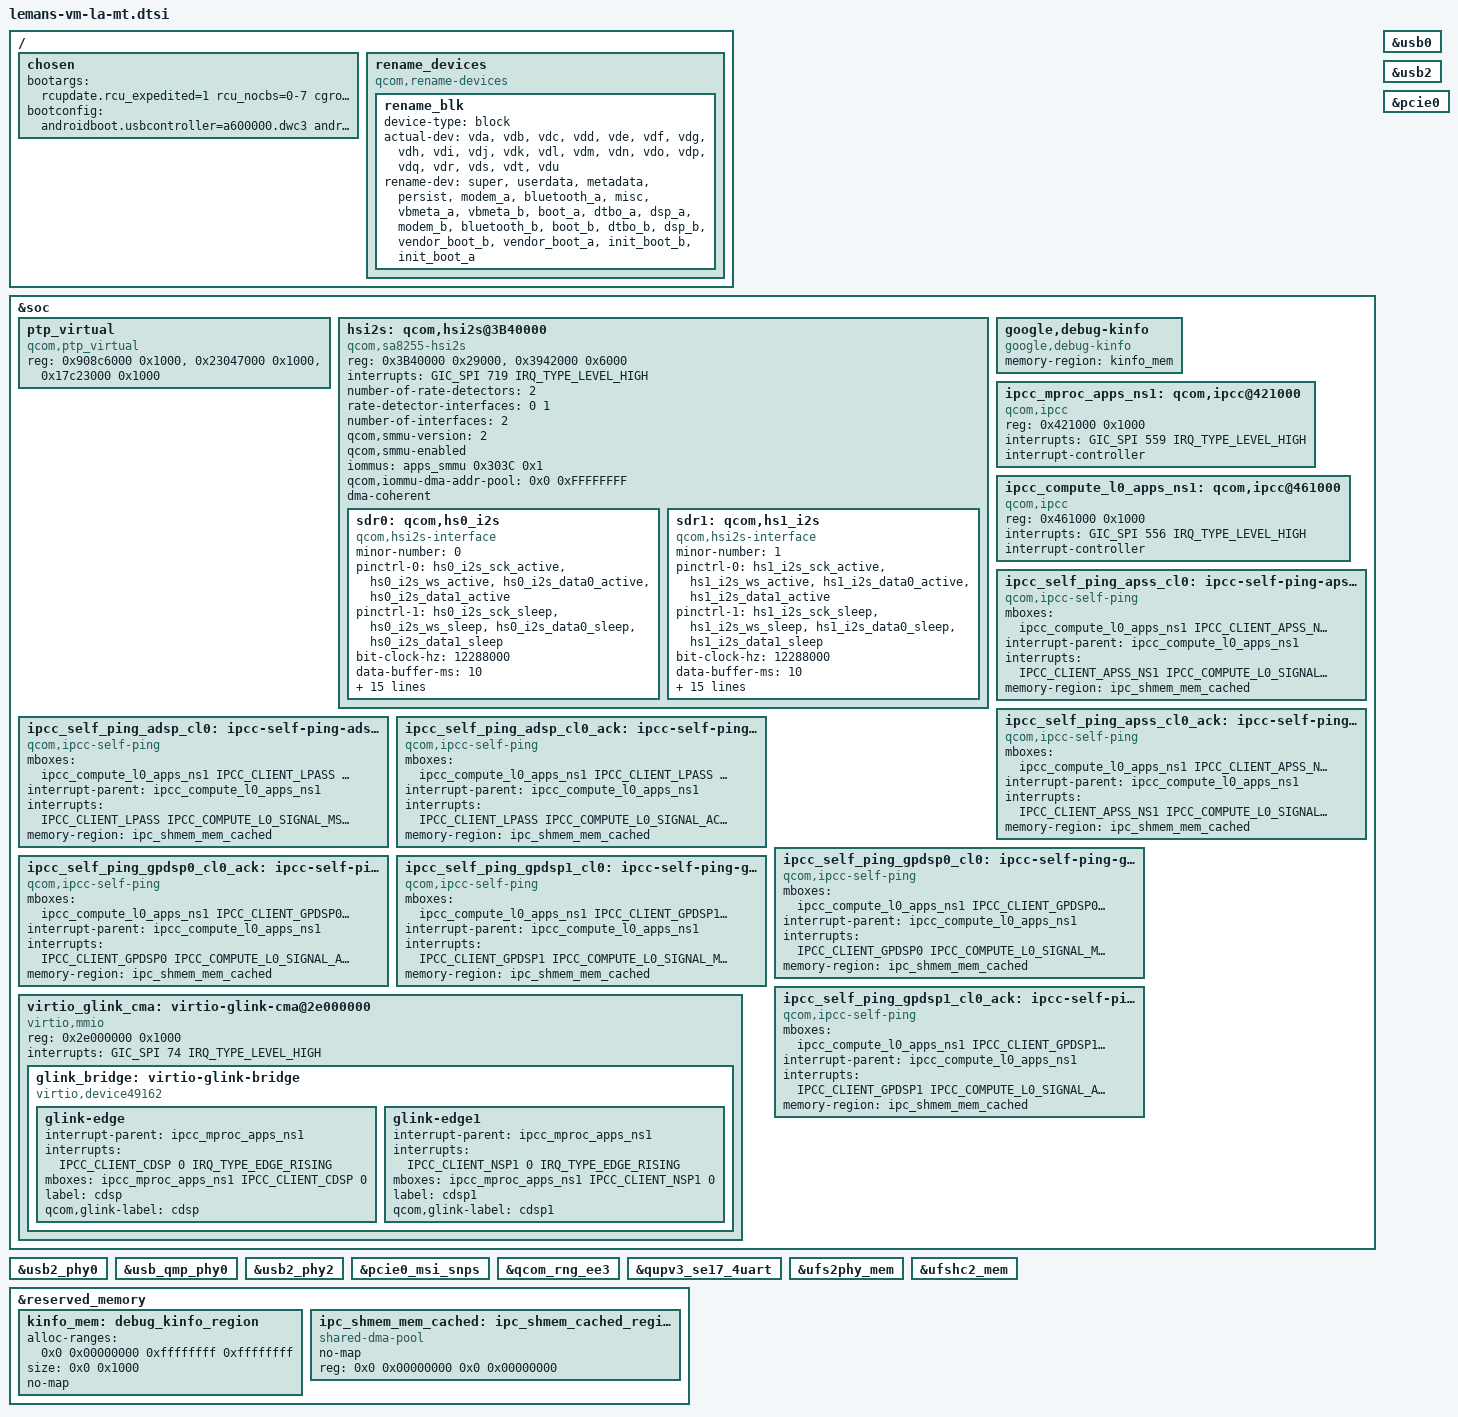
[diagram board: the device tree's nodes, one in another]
#include <dt-bindings/mailbox/qcom-ipcc.h>

&soc {
	ptp_virtual {
		compatible = "qcom,ptp_virtual";
		reg = <0x908c6000 0x1000>,
			<0x23047000 0x1000>,
			<0x17c23000 0x1000>;
		reg-names = "ptp_carveout_mem",
				"ptp_reg",
				"qtimer_reg";
	};

	hsi2s: qcom,hsi2s@3B40000 {
		compatible = "qcom,sa8255-hsi2s", "qcom,hsi2s";
		reg = <0x3B40000 0x29000>,
			<0x3942000 0x6000>;
		reg-names = "lpa_if", "lpass_core_cc_hs_if";
		interrupts = <GIC_SPI 719 IRQ_TYPE_LEVEL_HIGH>;
		number-of-rate-detectors = <2>;
		rate-detector-interfaces = <0 1>;
		number-of-interfaces = <2>;
		qcom,smmu-version = <2>;
		qcom,smmu-enabled;
		iommus = <&apps_smmu 0x303C 0x1>;
		qcom,iommu-dma-addr-pool = <0x0 0xFFFFFFFF>;
		dma-coherent;

		sdr0: qcom,hs0_i2s {
			compatible = "qcom,hsi2s-interface";
			minor-number = <0>;
			pinctrl-names = "default", "sleep";
			pinctrl-0 = <&hs0_i2s_sck_active
				     &hs0_i2s_ws_active &hs0_i2s_data0_active
				     &hs0_i2s_data1_active>;
			pinctrl-1 = <&hs0_i2s_sck_sleep
				     &hs0_i2s_ws_sleep &hs0_i2s_data0_sleep
				     &hs0_i2s_data1_sleep>;
			bit-clock-hz = <12288000>;
			data-buffer-ms = <10>;
			bit-depth = <32>;
			spkr-channel-count = <2>;
			mic-channel-count = <2>;
			pcm-rate = <2>;
			pcm-sync-src = <0>;
			aux-mode = <0>;
			rpcm-width = <1>;
			tpcm-width = <1>;
			enable-tdm = <1>;
			tdm-rate = <32>;
			tdm-rpcm-width = <16>;
			tdm-tpcm-width = <16>;
			tdm-sync-delay = <2>;
			tdm-inv-sync = <0>;
			pcm-lane-config = <1>;
		};

		sdr1: qcom,hs1_i2s {
			compatible = "qcom,hsi2s-interface";
			minor-number = <1>;
			pinctrl-names = "default", "sleep";
			pinctrl-0 = <&hs1_i2s_sck_active
				     &hs1_i2s_ws_active &hs1_i2s_data0_active
				     &hs1_i2s_data1_active>;
			pinctrl-1 = <&hs1_i2s_sck_sleep
				     &hs1_i2s_ws_sleep &hs1_i2s_data0_sleep
				     &hs1_i2s_data1_sleep>;
			bit-clock-hz = <12288000>;
			data-buffer-ms = <10>;
			bit-depth = <32>;
			spkr-channel-count = <2>;
			mic-channel-count = <2>;
			pcm-rate = <2>;
			pcm-sync-src = <0>;
			aux-mode = <0>;
			rpcm-width = <1>;
			tpcm-width = <1>;
			enable-tdm = <1>;
			tdm-rate = <32>;
			tdm-rpcm-width = <16>;
			tdm-tpcm-width = <16>;
			tdm-sync-delay = <2>;
			tdm-inv-sync = <0>;
			pcm-lane-config = <1>;
		};
	};
};

/ {
	chosen {
		bootargs = "rcupdate.rcu_expedited=1 rcu_nocbs=0-7 cgroup.memory=nokmem,nosocket kpti=0 ufshcd-core.use_mcq_mode=n arm64.nopauth kasan=off msm_show_resume_irq.debug_mask=1";
		bootconfig = "androidboot.usbcontroller=a600000.dwc3 androidboot.fstab_suffix=gen4.qcom androidboot.dtbo_idx=2";
	};

	rename_devices: rename_devices {
		compatible = "qcom,rename-devices";
		rename_blk: rename_blk {
			device-type = "block";
			actual-dev = "vda", "vdb", "vdc",
					"vdd", "vde", "vdf",
					"vdg", "vdh", "vdi",
					"vdj", "vdk", "vdl",
					"vdm", "vdn", "vdo",
					"vdp", "vdq", "vdr",
					"vds", "vdt", "vdu";
			rename-dev = "super", "userdata", "metadata",
					"persist", "modem_a","bluetooth_a",
					"misc", "vbmeta_a", "vbmeta_b",
					"boot_a", "dtbo_a", "dsp_a",
					"modem_b", "bluetooth_b", "boot_b",
					"dtbo_b", "dsp_b", "vendor_boot_b",
					"vendor_boot_a", "init_boot_b", "init_boot_a";
		};
	};
};

&usb0 {
	status = "ok";
};

&usb2_phy0 {
	status = "ok";
};

&usb_qmp_phy0 {
	status = "ok";
};

&usb2 {
	status = "ok";
};

&usb2_phy2 {
	status = "ok";
};

&pcie0 {
	status = "ok";
};

&pcie0_msi_snps {
	status = "ok";
};

&qcom_rng_ee3 {
	status = "ok";
};

&qupv3_se17_4uart {
	status = "ok";
};

&ufs2phy_mem {
	status = "ok";
};

&ufshc2_mem {
	status = "ok";
};

&reserved_memory {
	kinfo_mem: debug_kinfo_region {
		alloc-ranges = <0x0 0x00000000 0xffffffff 0xffffffff>;
		size = <0x0 0x1000>;
		no-map;
	};

	ipc_shmem_mem_cached: ipc_shmem_cached_region {
		compatible = "shared-dma-pool";
		no-map;
		reg = <0x0 0x00000000 0x0 0x00000000>;
	};
};

&soc {
	google,debug-kinfo {
		compatible = "google,debug-kinfo";
		memory-region = <&kinfo_mem>;
	};

	ipcc_mproc_apps_ns1: qcom,ipcc@421000 {
		compatible = "qcom,ipcc";
		reg = <0x421000 0x1000>;
		interrupts = <GIC_SPI 559 IRQ_TYPE_LEVEL_HIGH>;
		interrupt-controller;
		#interrupt-cells = <3>;
		#mbox-cells = <2>;
	};

	ipcc_compute_l0_apps_ns1: qcom,ipcc@461000 {
		compatible = "qcom,ipcc";
		reg = <0x461000 0x1000>;
		interrupts = <GIC_SPI 556 IRQ_TYPE_LEVEL_HIGH>;
		interrupt-controller;
		#interrupt-cells = <3>;
		#mbox-cells = <2>;
		status = "ok";
	};

	ipcc_self_ping_apss_cl0: ipcc-self-ping-apss_cl0 {
		compatible = "qcom,ipcc-self-ping";
		mboxes = <&ipcc_compute_l0_apps_ns1 IPCC_CLIENT_APSS_NS1
				IPCC_COMPUTE_L0_SIGNAL_MSG>;
		interrupt-parent = <&ipcc_compute_l0_apps_ns1>;
		interrupts = <IPCC_CLIENT_APSS_NS1
				IPCC_COMPUTE_L0_SIGNAL_MSG
				IRQ_TYPE_EDGE_RISING>;
		memory-region = <&ipc_shmem_mem_cached>;
	};

	ipcc_self_ping_apss_cl0_ack: ipcc-self-ping-apss_cl0_ack {
		compatible = "qcom,ipcc-self-ping";
		mboxes = <&ipcc_compute_l0_apps_ns1 IPCC_CLIENT_APSS_NS1
				IPCC_COMPUTE_L0_SIGNAL_ACK>;
		interrupt-parent = <&ipcc_compute_l0_apps_ns1>;
		interrupts = <IPCC_CLIENT_APSS_NS1
				IPCC_COMPUTE_L0_SIGNAL_ACK
				IRQ_TYPE_EDGE_RISING>;
		memory-region = <&ipc_shmem_mem_cached>;
	};

	ipcc_self_ping_adsp_cl0: ipcc-self-ping-adsp_cl0 {
		compatible = "qcom,ipcc-self-ping";
		mboxes = <&ipcc_compute_l0_apps_ns1 IPCC_CLIENT_LPASS
				IPCC_COMPUTE_L0_SIGNAL_MSG>;
		interrupt-parent = <&ipcc_compute_l0_apps_ns1>;
		interrupts = <IPCC_CLIENT_LPASS
				IPCC_COMPUTE_L0_SIGNAL_MSG
				IRQ_TYPE_EDGE_RISING>;
		memory-region = <&ipc_shmem_mem_cached>;
	};

	ipcc_self_ping_adsp_cl0_ack: ipcc-self-ping-adsp_cl0_ack {
		compatible = "qcom,ipcc-self-ping";
		mboxes = <&ipcc_compute_l0_apps_ns1 IPCC_CLIENT_LPASS
				IPCC_COMPUTE_L0_SIGNAL_ACK>;
		interrupt-parent = <&ipcc_compute_l0_apps_ns1>;
		interrupts = <IPCC_CLIENT_LPASS
				IPCC_COMPUTE_L0_SIGNAL_ACK
				IRQ_TYPE_EDGE_RISING>;
		memory-region = <&ipc_shmem_mem_cached>;
	};

	ipcc_self_ping_gpdsp0_cl0: ipcc-self-ping-gpdsp0_cl0 {
		compatible = "qcom,ipcc-self-ping";
		mboxes = <&ipcc_compute_l0_apps_ns1 IPCC_CLIENT_GPDSP0
				IPCC_COMPUTE_L0_SIGNAL_MSG>;
		interrupt-parent = <&ipcc_compute_l0_apps_ns1>;
		interrupts = <IPCC_CLIENT_GPDSP0
				IPCC_COMPUTE_L0_SIGNAL_MSG
				IRQ_TYPE_EDGE_RISING>;
		memory-region = <&ipc_shmem_mem_cached>;
	};

	ipcc_self_ping_gpdsp0_cl0_ack: ipcc-self-ping-gpdsp0_cl0_ack {
		compatible = "qcom,ipcc-self-ping";
		mboxes = <&ipcc_compute_l0_apps_ns1 IPCC_CLIENT_GPDSP0
				IPCC_COMPUTE_L0_SIGNAL_ACK>;
		interrupt-parent = <&ipcc_compute_l0_apps_ns1>;
		interrupts = <IPCC_CLIENT_GPDSP0
				IPCC_COMPUTE_L0_SIGNAL_ACK
				IRQ_TYPE_EDGE_RISING>;
		memory-region = <&ipc_shmem_mem_cached>;
	};

	ipcc_self_ping_gpdsp1_cl0: ipcc-self-ping-gpdsp1_cl0 {
		compatible = "qcom,ipcc-self-ping";
		mboxes = <&ipcc_compute_l0_apps_ns1 IPCC_CLIENT_GPDSP1
				IPCC_COMPUTE_L0_SIGNAL_MSG>;
		interrupt-parent = <&ipcc_compute_l0_apps_ns1>;
		interrupts = <IPCC_CLIENT_GPDSP1
				IPCC_COMPUTE_L0_SIGNAL_MSG
				IRQ_TYPE_EDGE_RISING>;
		memory-region = <&ipc_shmem_mem_cached>;
	};

	ipcc_self_ping_gpdsp1_cl0_ack: ipcc-self-ping-gpdsp1_cl0_ack {
		compatible = "qcom,ipcc-self-ping";
		mboxes = <&ipcc_compute_l0_apps_ns1 IPCC_CLIENT_GPDSP1
				IPCC_COMPUTE_L0_SIGNAL_ACK>;
		interrupt-parent = <&ipcc_compute_l0_apps_ns1>;
		interrupts = <IPCC_CLIENT_GPDSP1
				IPCC_COMPUTE_L0_SIGNAL_ACK
				IRQ_TYPE_EDGE_RISING>;
		memory-region = <&ipc_shmem_mem_cached>;
	};

	virtio_glink_cma: virtio-glink-cma@2e000000 {
		compatible = "virtio,mmio";
		reg = <0x2e000000 0x1000>;
		interrupts = <GIC_SPI 74 IRQ_TYPE_LEVEL_HIGH>;

		glink_bridge: virtio-glink-bridge {
			compatible = "virtio,device49162"; /* VIRTIO_ID: 0xC00A */

			glink-edge {
				interrupt-parent = <&ipcc_mproc_apps_ns1>;
				interrupts = <IPCC_CLIENT_CDSP 0 IRQ_TYPE_EDGE_RISING>;
				mboxes = <&ipcc_mproc_apps_ns1 IPCC_CLIENT_CDSP 0>;
				label = "cdsp";
				qcom,glink-label = "cdsp";
			};

			glink-edge1 {
				interrupt-parent = <&ipcc_mproc_apps_ns1>;
				interrupts = <IPCC_CLIENT_NSP1 0 IRQ_TYPE_EDGE_RISING>;
				mboxes = <&ipcc_mproc_apps_ns1 IPCC_CLIENT_NSP1 0>;
				label = "cdsp1";
				qcom,glink-label = "cdsp1";
			};
		};
	};
};
